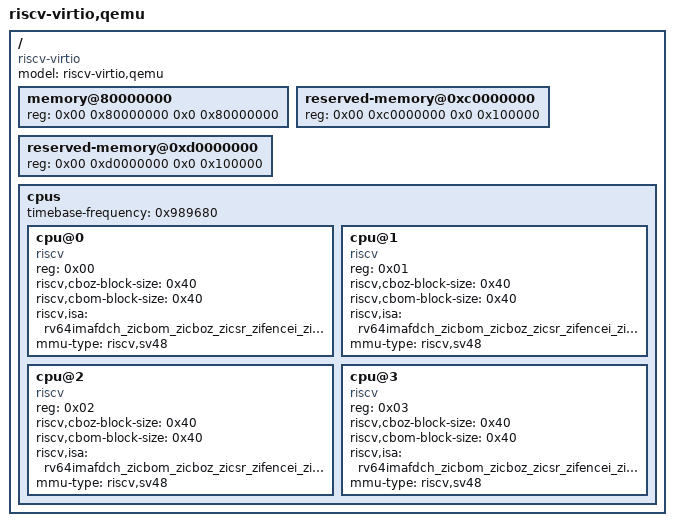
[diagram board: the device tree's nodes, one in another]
/dts-v1/;

/ {
	#address-cells = <0x02>;
	#size-cells = <0x02>;
	compatible = "riscv-virtio";
	model = "riscv-virtio,qemu";
	memory@80000000 {
		device_type = "memory";
		reg = <0x00 0x80000000 0x0 0x80000000>;
	};

	reserved-memory@0xc0000000 {
		device_type = "reserved-memory";
		reg = <0x00 0xc0000000 0x0 0x100000>;
	};

	reserved-memory@0xd0000000 {
		device_type = "reserved-memory";
		reg = <0x00 0xd0000000 0x0 0x100000>;
	};

	cpus {
		#address-cells = <0x01>;
		#size-cells = <0x00>;
		timebase-frequency = <0x989680>;

		cpu@0 {
			phandle = <0x01>;
			device_type = "cpu";
			reg = <0x00>;
			status = "okay";
			compatible = "riscv";
			riscv,cboz-block-size = <0x40>;
			riscv,cbom-block-size = <0x40>;
			riscv,isa = "rv64imafdch_zicbom_zicboz_zicsr_zifencei_zihintpause_zawrs_zfa_zca_zcd_zba_zbb_zbc_zbs_smaia_ssaia_sstc_svadu";
			mmu-type = "riscv,sv48";
		};
		cpu@1 {
			phandle = <0x02>;
			device_type = "cpu";
			reg = <0x01>;
			status = "okay";
			compatible = "riscv";
			riscv,cboz-block-size = <0x40>;
			riscv,cbom-block-size = <0x40>;
			riscv,isa = "rv64imafdch_zicbom_zicboz_zicsr_zifencei_zihintpause_zawrs_zfa_zca_zcd_zba_zbb_zbc_zbs_smaia_ssaia_sstc_svadu";
			mmu-type = "riscv,sv48";
		};

		cpu@2 {
			phandle = <0x03>;
			device_type = "cpu";
			reg = <0x02>;
			status = "okay";
			compatible = "riscv";
			riscv,cboz-block-size = <0x40>;
			riscv,cbom-block-size = <0x40>;
			riscv,isa = "rv64imafdch_zicbom_zicboz_zicsr_zifencei_zihintpause_zawrs_zfa_zca_zcd_zba_zbb_zbc_zbs_smaia_ssaia_sstc_svadu";
			mmu-type = "riscv,sv48";
		};
		cpu@3 {
			phandle = <0x04>;
			device_type = "cpu";
			reg = <0x03>;
			status = "okay";
			compatible = "riscv";
			riscv,cboz-block-size = <0x40>;
			riscv,cbom-block-size = <0x40>;
			riscv,isa = "rv64imafdch_zicbom_zicboz_zicsr_zifencei_zihintpause_zawrs_zfa_zca_zcd_zba_zbb_zbc_zbs_smaia_ssaia_sstc_svadu";
			mmu-type = "riscv,sv48";
		};
	};
};
